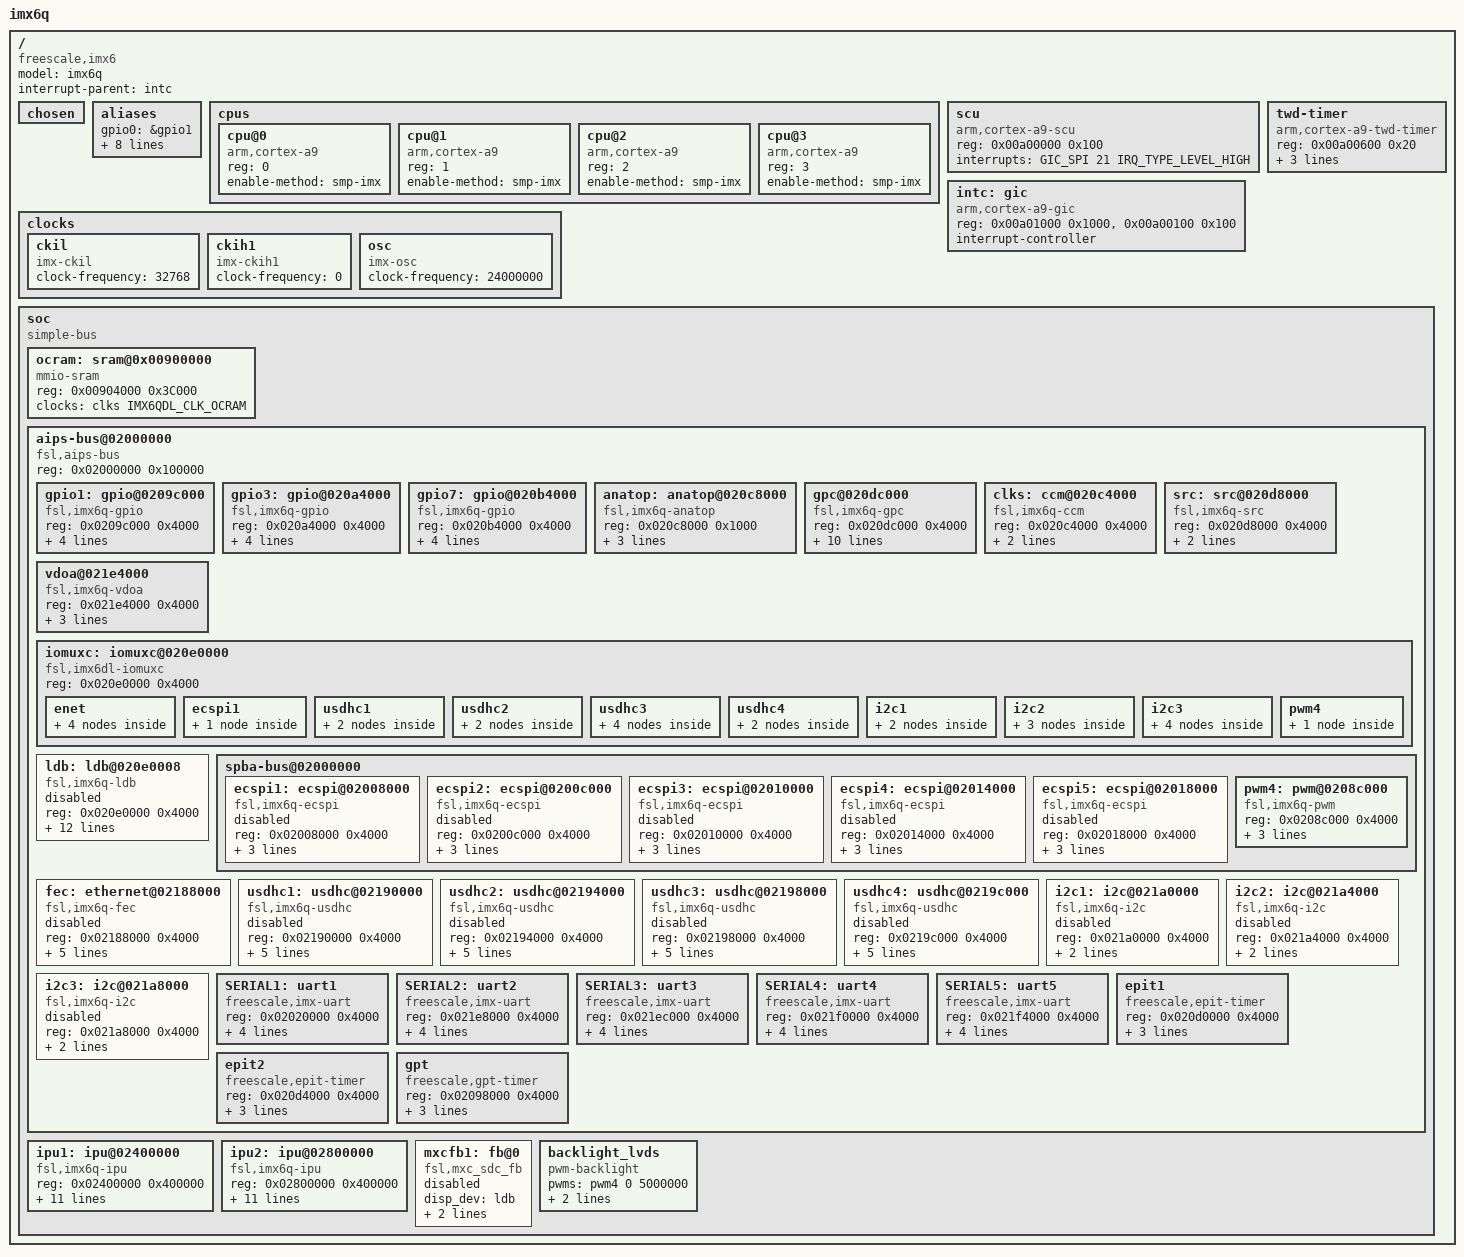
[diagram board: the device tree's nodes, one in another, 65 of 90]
/*
 * Copyright (C) 2014 Institut de Recherche Technologique SystemX and OpenWide.
 * Originally from Jean-Christophe Dubois, and modified by
 * Jimmy Durand Wesolowski (jimmy.durand-wesolowski@openwide.fr)
 * to split device tree files between i.MX6-specific and Sabrelite-specific
 * definitions, and add the Anatop definition.
 * Inspired by the Linux Kernel 3.13.6 i.MX6 device tree file.
 */

#include "imx6q-pinfunc.h"
#include <imx6qdl-clock.h>
#include <dt-bindings/interrupt-controller/arm-gic.h>

/memreserve/ 0x10000000 0x00001000;

/ {
	compatible = "freescale,imx6";
	model = "imx6q";
	interrupt-parent = <&intc>;
	#address-cells = <1>;
	#size-cells = <1>;

	chosen { };

	aliases {
                gpio0 = &gpio1;
                gpio2 = &gpio3;
                gpio6 = &gpio7;
		ipu0 = &ipu1;
		ipu1 = &ipu2;
		i2c0 = &i2c1;
		i2c1 = &i2c2;
		i2c2 = &i2c3;
                spi0 = &ecspi1;
	};

	cpus {
		#address-cells = <1>;
		#size-cells = <0>;

		cpu@0 {
			device_type = "cpu";
			compatible = "arm,cortex-a9";
			reg = <0>;
			enable-method = "smp-imx";
		};

		cpu@1 {
			device_type = "cpu";
			compatible = "arm,cortex-a9";
			reg = <1>;
			enable-method = "smp-imx";
		};

		cpu@2 {
			device_type = "cpu";
			compatible = "arm,cortex-a9";
			reg = <2>;
			enable-method = "smp-imx";
		};

		cpu@3 {
			device_type = "cpu";
			compatible = "arm,cortex-a9";
			reg = <3>;
			enable-method = "smp-imx";
		};
	};

        clocks {
		#address-cells = <1>;
		#size-cells = <0>;

		ckil {
			compatible = "imx-ckil", "fixed-clock";
			clock-frequency = <32768>;
		};

		ckih1 {
			compatible = "imx-ckih1", "fixed-clock";
			clock-frequency = <0>;
		};

		osc {
			compatible = "imx-osc", "fixed-clock";
			clock-frequency = <24000000>;
		};
	};

	scu { /* Snoop Control Unit */
      		compatible = "arm,cortex-a9-scu";
      		reg = <0x00a00000 0x100>;
		interrupts = <GIC_SPI 21 IRQ_TYPE_LEVEL_HIGH>;
	};

	intc: gic { /* Generic Interrupt Controller */
      		compatible = "arm,cortex-a9-gic";
		reg = <0x00a01000 0x1000>,
		      <0x00a00100 0x100>;
		#interrupt-cells = <3>;
		interrupt-controller;
	};

	twd-timer { /* Local Timer */
      		compatible = "arm,cortex-a9-twd-timer";
      		reg = <0x00a00600 0x20>;	/* Local timer registers */
		ref-counter-freq = <24000000>;	/* Reference counter frequency */
		interrupts = <GIC_PPI 13 (GIC_CPU_MASK_RAW(0xf) | IRQ_TYPE_EDGE_RISING)>;
	};

	soc {
		#address-cells = <1>;
		#size-cells = <1>;
		compatible = "simple-bus";

		ocram: sram@0x00900000 {
			compatible = "mmio-sram";
			reg = <0x00904000 0x3C000>;
			clocks = <&clks IMX6QDL_CLK_OCRAM>;
		};

		aips-bus@02000000 { /* AIPS1 */
			compatible = "fsl,aips-bus", "simple-bus";
			#address-cells = <1>;
			#size-cells = <1>;
			reg = <0x02000000 0x100000>;
			ranges;

			gpio1: gpio@0209c000 {
				compatible = "fsl,imx6q-gpio", "fsl,imx35-gpio";
				reg = <0x0209c000 0x4000>;
				interrupts = <GIC_SPI 66 IRQ_TYPE_LEVEL_HIGH>,
					     <GIC_SPI 67 IRQ_TYPE_LEVEL_HIGH>;
				gpio-controller;
				#gpio-cells = <2>;
				interrupt-controller;
				#interrupt-cells = <2>;
			};

			gpio3: gpio@020a4000 {
				compatible = "fsl,imx6q-gpio", "fsl,imx35-gpio";
				reg = <0x020a4000 0x4000>;
				interrupts = <GIC_SPI 70 IRQ_TYPE_LEVEL_HIGH>,
					     <GIC_SPI 71 IRQ_TYPE_LEVEL_HIGH>;
				gpio-controller;
				#gpio-cells = <2>;
				interrupt-controller;
				#interrupt-cells = <2>;
			};

			gpio7: gpio@020b4000 {
				compatible = "fsl,imx6q-gpio", "fsl,imx35-gpio";
				reg = <0x020b4000 0x4000>;
				interrupts = <GIC_SPI 78 IRQ_TYPE_LEVEL_HIGH>,
					     <GIC_SPI 79 IRQ_TYPE_LEVEL_HIGH>;
				gpio-controller;
				#gpio-cells = <2>;
				interrupt-controller;
				#interrupt-cells = <2>;
			};

			anatop: anatop@020c8000 {
				compatible = "fsl,imx6q-anatop", "syscon", "simple-bus";
				reg = <0x020c8000 0x1000>;
				interrupts = <GIC_SPI 49 IRQ_TYPE_LEVEL_HIGH>,
					     <GIC_SPI 54 IRQ_TYPE_LEVEL_HIGH>,
					     <GIC_SPI 127 IRQ_TYPE_LEVEL_HIGH>;
			};

			gpc@020dc000 {
				compatible = "fsl,imx6q-gpc";
				reg = <0x020dc000 0x4000>;
				interrupt-controller;
				#interrupt-cells = <3>;
				interrupts = <GIC_SPI 89 IRQ_TYPE_LEVEL_HIGH>,
					     <GIC_SPI 90 IRQ_TYPE_LEVEL_HIGH>;
				interrupt-parent = <&intc>;
				//pu-supply = <&reg_pu>;
				clocks = <&clks IMX6QDL_CLK_GPU3D_CORE>,
					 <&clks IMX6QDL_CLK_GPU3D_SHADER>,
					 <&clks IMX6QDL_CLK_GPU2D_CORE>,
					 <&clks IMX6QDL_CLK_GPU2D_AXI>,
					 <&clks IMX6QDL_CLK_OPENVG_AXI>,
					 <&clks IMX6QDL_CLK_VPU_AXI>;
				#power-domain-cells = <1>;
			};

			clks: ccm@020c4000 {
				compatible = "fsl,imx6q-ccm";
				reg = <0x020c4000 0x4000>;
				interrupts = <GIC_SPI 87 IRQ_TYPE_LEVEL_HIGH>,
					     <GIC_SPI 88 IRQ_TYPE_LEVEL_HIGH>;
				#clock-cells = <1>;
			};

			src: src@020d8000 {
				compatible = "fsl,imx6q-src", "fsl,imx51-src";
				reg = <0x020d8000 0x4000>;
				interrupts = <GIC_SPI 91 IRQ_TYPE_LEVEL_HIGH>,
					     <GIC_SPI 96 IRQ_TYPE_LEVEL_HIGH>;
				#reset-cells = <1>;
			};

			vdoa@021e4000 {
				compatible = "fsl,imx6q-vdoa";
				reg = <0x021e4000 0x4000>;
				interrupts = <GIC_SPI 8 IRQ_TYPE_LEVEL_HIGH>;
				clocks = <&clks IMX6QDL_CLK_VDOA>;
				iram = <&ocram>;
			};

			iomuxc: iomuxc@020e0000 {
				compatible = "fsl,imx6dl-iomuxc", "fsl,imx6q-iomuxc";
				reg = <0x020e0000 0x4000>;

				enet {
					pinctrl_enet_1: enetgrp-1 {
						fsl,pins = <
							MX6QDL_PAD_ENET_MDIO__ENET_MDIO       0x1b0b0
							MX6QDL_PAD_ENET_MDC__ENET_MDC         0x1b0b0
							MX6QDL_PAD_RGMII_TXC__RGMII_TXC       0x1b0b0
							MX6QDL_PAD_RGMII_TD0__RGMII_TD0       0x1b0b0
							MX6QDL_PAD_RGMII_TD1__RGMII_TD1       0x1b0b0
							MX6QDL_PAD_RGMII_TD2__RGMII_TD2       0x1b0b0
							MX6QDL_PAD_RGMII_TD3__RGMII_TD3       0x1b0b0
							MX6QDL_PAD_RGMII_TX_CTL__RGMII_TX_CTL 0x1b0b0
							MX6QDL_PAD_ENET_REF_CLK__ENET_TX_CLK  0x1b0b0
							MX6QDL_PAD_RGMII_RXC__RGMII_RXC       0x1b0b0
							MX6QDL_PAD_RGMII_RD0__RGMII_RD0       0x1b0b0
							MX6QDL_PAD_RGMII_RD1__RGMII_RD1       0x1b0b0
							MX6QDL_PAD_RGMII_RD2__RGMII_RD2       0x1b0b0
							MX6QDL_PAD_RGMII_RD3__RGMII_RD3       0x1b0b0
							MX6QDL_PAD_RGMII_RX_CTL__RGMII_RX_CTL 0x1b0b0
							MX6QDL_PAD_GPIO_16__ENET_REF_CLK      0x4001b0a8
						>;
					};

					pinctrl_enet_2: enetgrp-2 {
						fsl,pins = <
							MX6QDL_PAD_KEY_COL1__ENET_MDIO        0x1b0b0
							MX6QDL_PAD_KEY_COL2__ENET_MDC         0x1b0b0
							MX6QDL_PAD_RGMII_TXC__RGMII_TXC       0x1b0b0
							MX6QDL_PAD_RGMII_TD0__RGMII_TD0       0x1b0b0
							MX6QDL_PAD_RGMII_TD1__RGMII_TD1       0x1b0b0
							MX6QDL_PAD_RGMII_TD2__RGMII_TD2       0x1b0b0
							MX6QDL_PAD_RGMII_TD3__RGMII_TD3       0x1b0b0
							MX6QDL_PAD_RGMII_TX_CTL__RGMII_TX_CTL 0x1b0b0
							MX6QDL_PAD_ENET_REF_CLK__ENET_TX_CLK  0x1b0b0
							MX6QDL_PAD_RGMII_RXC__RGMII_RXC       0x1b0b0
							MX6QDL_PAD_RGMII_RD0__RGMII_RD0       0x1b0b0
							MX6QDL_PAD_RGMII_RD1__RGMII_RD1       0x1b0b0
							MX6QDL_PAD_RGMII_RD2__RGMII_RD2       0x1b0b0
							MX6QDL_PAD_RGMII_RD3__RGMII_RD3       0x1b0b0
							MX6QDL_PAD_RGMII_RX_CTL__RGMII_RX_CTL 0x1b0b0
						>;
					};

					pinctrl_enet_3: enetgrp-3 {
						fsl,pins = <
							MX6QDL_PAD_ENET_MDIO__ENET_MDIO       0x1b0b0
							MX6QDL_PAD_ENET_MDC__ENET_MDC         0x1b0b0
							MX6QDL_PAD_RGMII_TXC__RGMII_TXC       0x1b0b0
							MX6QDL_PAD_RGMII_TD0__RGMII_TD0       0x1b0b0
							MX6QDL_PAD_RGMII_TD1__RGMII_TD1       0x1b0b0
							MX6QDL_PAD_RGMII_TD2__RGMII_TD2       0x1b0b0
							MX6QDL_PAD_RGMII_TD3__RGMII_TD3       0x1b0b0
							MX6QDL_PAD_RGMII_TX_CTL__RGMII_TX_CTL 0x1b0b0
							MX6QDL_PAD_ENET_REF_CLK__ENET_TX_CLK  0x1b0b0
							MX6QDL_PAD_RGMII_RXC__RGMII_RXC       0x1b0b0
							MX6QDL_PAD_RGMII_RD0__RGMII_RD0       0x1b0b0
							MX6QDL_PAD_RGMII_RD1__RGMII_RD1       0x1b0b0
							MX6QDL_PAD_RGMII_RD2__RGMII_RD2       0x1b0b0
							MX6QDL_PAD_RGMII_RD3__RGMII_RD3       0x1b0b0
							MX6QDL_PAD_RGMII_RX_CTL__RGMII_RX_CTL 0x1b0b0
							MX6QDL_PAD_ENET_TX_EN__ENET_TX_EN     0x1b0b0
						>;
					};

					pinctrl_enet_4: enetgrp-4 {
						fsl,pins = <
							MX6QDL_PAD_ENET_MDIO__ENET_MDIO       0x100b0
							MX6QDL_PAD_ENET_MDC__ENET_MDC         0x100b0
							MX6QDL_PAD_RGMII_TXC__RGMII_TXC       0x100b0
							MX6QDL_PAD_RGMII_TD0__RGMII_TD0       0x100b0
							MX6QDL_PAD_RGMII_TD1__RGMII_TD1       0x100b0
							MX6QDL_PAD_RGMII_TD2__RGMII_TD2       0x100b0
							MX6QDL_PAD_RGMII_TD3__RGMII_TD3       0x100b0
							MX6QDL_PAD_RGMII_TX_CTL__RGMII_TX_CTL 0x100b0
							MX6QDL_PAD_ENET_REF_CLK__ENET_TX_CLK  0x100b0
							MX6QDL_PAD_RGMII_RXC__RGMII_RXC       0x1b0b0
							MX6QDL_PAD_RGMII_RD0__RGMII_RD0       0x1b0b0
							MX6QDL_PAD_RGMII_RD1__RGMII_RD1       0x1b0b0
							MX6QDL_PAD_RGMII_RD2__RGMII_RD2       0x1b0b0
							MX6QDL_PAD_RGMII_RD3__RGMII_RD3       0x1b0b0
							MX6QDL_PAD_RGMII_RX_CTL__RGMII_RX_CTL 0x1b0b0
						>;
					};
				};

				ecspi1 {
					pinctrl_ecspi1_1: ecspi1grp-1 {
						fsl,pins = <
							MX6QDL_PAD_EIM_D17__ECSPI1_MISO 0x100b1
							MX6QDL_PAD_EIM_D18__ECSPI1_MOSI 0x100b1
							MX6QDL_PAD_EIM_D16__ECSPI1_SCLK 0x100b1
						>;
					};
				};

				usdhc1 {
					pinctrl_usdhc1_1: usdhc1grp-1 {
						fsl,pins = <
							MX6QDL_PAD_SD1_CMD__SD1_CMD    0x17059
							MX6QDL_PAD_SD1_CLK__SD1_CLK    0x10059
							MX6QDL_PAD_SD1_DAT0__SD1_DATA0 0x17059
							MX6QDL_PAD_SD1_DAT1__SD1_DATA1 0x17059
							MX6QDL_PAD_SD1_DAT2__SD1_DATA2 0x17059
							MX6QDL_PAD_SD1_DAT3__SD1_DATA3 0x17059
							MX6QDL_PAD_NANDF_D0__SD1_DATA4 0x17059
							MX6QDL_PAD_NANDF_D1__SD1_DATA5 0x17059
							MX6QDL_PAD_NANDF_D2__SD1_DATA6 0x17059
							MX6QDL_PAD_NANDF_D3__SD1_DATA7 0x17059
						>;
					};

					pinctrl_usdhc1_2: usdhc1grp-2 {
						fsl,pins = <
							MX6QDL_PAD_SD1_CMD__SD1_CMD    0x17059
							MX6QDL_PAD_SD1_CLK__SD1_CLK    0x10059
							MX6QDL_PAD_SD1_DAT0__SD1_DATA0 0x17059
							MX6QDL_PAD_SD1_DAT1__SD1_DATA1 0x17059
							MX6QDL_PAD_SD1_DAT2__SD1_DATA2 0x17059
							MX6QDL_PAD_SD1_DAT3__SD1_DATA3 0x17059
						>;
					};
				};

				usdhc2 {
					pinctrl_usdhc2_1: usdhc2grp-1 {
						fsl,pins = <
							MX6QDL_PAD_SD2_CMD__SD2_CMD    0x17059
							MX6QDL_PAD_SD2_CLK__SD2_CLK    0x10059
							MX6QDL_PAD_SD2_DAT0__SD2_DATA0 0x17059
							MX6QDL_PAD_SD2_DAT1__SD2_DATA1 0x17059
							MX6QDL_PAD_SD2_DAT2__SD2_DATA2 0x17059
							MX6QDL_PAD_SD2_DAT3__SD2_DATA3 0x17059
							MX6QDL_PAD_NANDF_D4__SD2_DATA4 0x17059
							MX6QDL_PAD_NANDF_D5__SD2_DATA5 0x17059
							MX6QDL_PAD_NANDF_D6__SD2_DATA6 0x17059
							MX6QDL_PAD_NANDF_D7__SD2_DATA7 0x17059
						>;
					};

					pinctrl_usdhc2_2: usdhc2grp-2 {
						fsl,pins = <
							MX6QDL_PAD_SD2_CMD__SD2_CMD    0x17059
							MX6QDL_PAD_SD2_CLK__SD2_CLK    0x10059
							MX6QDL_PAD_SD2_DAT0__SD2_DATA0 0x17059
							MX6QDL_PAD_SD2_DAT1__SD2_DATA1 0x17059
							MX6QDL_PAD_SD2_DAT2__SD2_DATA2 0x17059
							MX6QDL_PAD_SD2_DAT3__SD2_DATA3 0x17059
						>;
					};
				};

				usdhc3 {
					pinctrl_usdhc3_1: usdhc3grp-1 {
						fsl,pins = <
							MX6QDL_PAD_SD3_CMD__SD3_CMD    0x17059
							MX6QDL_PAD_SD3_CLK__SD3_CLK    0x10059
							MX6QDL_PAD_SD3_DAT0__SD3_DATA0 0x17059
							MX6QDL_PAD_SD3_DAT1__SD3_DATA1 0x17059
							MX6QDL_PAD_SD3_DAT2__SD3_DATA2 0x17059
							MX6QDL_PAD_SD3_DAT3__SD3_DATA3 0x17059
							MX6QDL_PAD_SD3_DAT4__SD3_DATA4 0x17059
							MX6QDL_PAD_SD3_DAT5__SD3_DATA5 0x17059
							MX6QDL_PAD_SD3_DAT6__SD3_DATA6 0x17059
							MX6QDL_PAD_SD3_DAT7__SD3_DATA7 0x17059
						>;
					};

					pinctrl_usdhc3_1_100mhz: usdhc3grp-1-100mhz { /* 100Mhz */
						fsl,pins = <
							MX6QDL_PAD_SD3_CMD__SD3_CMD 0x170b9
							MX6QDL_PAD_SD3_CLK__SD3_CLK 0x100b9
							MX6QDL_PAD_SD3_DAT0__SD3_DATA0 0x170b9
							MX6QDL_PAD_SD3_DAT1__SD3_DATA1 0x170b9
							MX6QDL_PAD_SD3_DAT2__SD3_DATA2 0x170b9
							MX6QDL_PAD_SD3_DAT3__SD3_DATA3 0x170b9
							MX6QDL_PAD_SD3_DAT4__SD3_DATA4 0x170b9
							MX6QDL_PAD_SD3_DAT5__SD3_DATA5 0x170b9
							MX6QDL_PAD_SD3_DAT6__SD3_DATA6 0x170b9
							MX6QDL_PAD_SD3_DAT7__SD3_DATA7 0x170b9
						>;
					};

					pinctrl_usdhc3_1_200mhz: usdhc3grp-1-200mhz { /* 200Mhz */
						fsl,pins = <
							MX6QDL_PAD_SD3_CMD__SD3_CMD 0x170f9
							MX6QDL_PAD_SD3_CLK__SD3_CLK 0x100f9
							MX6QDL_PAD_SD3_DAT0__SD3_DATA0 0x170f9
							MX6QDL_PAD_SD3_DAT1__SD3_DATA1 0x170f9
							MX6QDL_PAD_SD3_DAT2__SD3_DATA2 0x170f9
							MX6QDL_PAD_SD3_DAT3__SD3_DATA3 0x170f9
							MX6QDL_PAD_SD3_DAT4__SD3_DATA4 0x170f9
							MX6QDL_PAD_SD3_DAT5__SD3_DATA5 0x170f9
							MX6QDL_PAD_SD3_DAT6__SD3_DATA6 0x170f9
							MX6QDL_PAD_SD3_DAT7__SD3_DATA7 0x170f9
						>;
					};

					pinctrl_usdhc3_2: usdhc3grp-2 {
						fsl,pins = <
							MX6QDL_PAD_SD3_CMD__SD3_CMD    0x17059
							MX6QDL_PAD_SD3_CLK__SD3_CLK    0x10059
							MX6QDL_PAD_SD3_DAT0__SD3_DATA0 0x17059
							MX6QDL_PAD_SD3_DAT1__SD3_DATA1 0x17059
							MX6QDL_PAD_SD3_DAT2__SD3_DATA2 0x17059
							MX6QDL_PAD_SD3_DAT3__SD3_DATA3 0x17059
						>;
					};
				};

				usdhc4 {
					pinctrl_usdhc4_1: usdhc4grp-1 {
						fsl,pins = <
							MX6QDL_PAD_SD4_CMD__SD4_CMD    0x17059
							MX6QDL_PAD_SD4_CLK__SD4_CLK    0x10059
							MX6QDL_PAD_SD4_DAT0__SD4_DATA0 0x17059
							MX6QDL_PAD_SD4_DAT1__SD4_DATA1 0x17059
							MX6QDL_PAD_SD4_DAT2__SD4_DATA2 0x17059
							MX6QDL_PAD_SD4_DAT3__SD4_DATA3 0x17059
							MX6QDL_PAD_SD4_DAT4__SD4_DATA4 0x17059
							MX6QDL_PAD_SD4_DAT5__SD4_DATA5 0x17059
							MX6QDL_PAD_SD4_DAT6__SD4_DATA6 0x17059
							MX6QDL_PAD_SD4_DAT7__SD4_DATA7 0x17059
						>;
					};

					pinctrl_usdhc4_2: usdhc4grp-2 {
						fsl,pins = <
							MX6QDL_PAD_SD4_CMD__SD4_CMD    0x17059
							MX6QDL_PAD_SD4_CLK__SD4_CLK    0x10059
							MX6QDL_PAD_SD4_DAT0__SD4_DATA0 0x17059
							MX6QDL_PAD_SD4_DAT1__SD4_DATA1 0x17059
							MX6QDL_PAD_SD4_DAT2__SD4_DATA2 0x17059
							MX6QDL_PAD_SD4_DAT3__SD4_DATA3 0x17059
						>;
					};
				};

				i2c1 {
					pinctrl_i2c1_1: i2c1grp-1 {
						fsl,pins = <
							MX6QDL_PAD_EIM_D21__I2C1_SCL 0x4001b8b1
							MX6QDL_PAD_EIM_D28__I2C1_SDA 0x4001b8b1
						>;
					};

					pinctrl_i2c1_2: i2c1grp-2 {
						fsl,pins = <
							MX6QDL_PAD_CSI0_DAT8__I2C1_SDA 0x4001b8b1
							MX6QDL_PAD_CSI0_DAT9__I2C1_SCL 0x4001b8b1
						>;
					};
				};

				i2c2 {
					pinctrl_i2c2_1: i2c2grp-1 {
						fsl,pins = <
							MX6QDL_PAD_EIM_EB2__I2C2_SCL 0x4001b8b1
							MX6QDL_PAD_EIM_D16__I2C2_SDA 0x4001b8b1
						>;
					};

					pinctrl_i2c2_2: i2c2grp-2 {
						fsl,pins = <
							MX6QDL_PAD_KEY_COL3__I2C2_SCL 0x4001b8b1
							MX6QDL_PAD_KEY_ROW3__I2C2_SDA 0x4001b8b1
						>;
					};

					pinctrl_i2c2_3: i2c2grp-3 {
						fsl,pins = <
							MX6QDL_PAD_EIM_EB2__I2C2_SCL  0x4001b8b1
							MX6QDL_PAD_KEY_ROW3__I2C2_SDA 0x4001b8b1
						>;
					};
				};

				i2c3 {
					pinctrl_i2c3_1: i2c3grp-1 {
						fsl,pins = <
							MX6QDL_PAD_EIM_D17__I2C3_SCL 0x4001b8b1
							MX6QDL_PAD_EIM_D18__I2C3_SDA 0x4001b8b1
						>;
					};

					pinctrl_i2c3_2: i2c3grp-2 {
						fsl,pins = <
							MX6QDL_PAD_GPIO_3__I2C3_SCL 0x4001b8b1
							MX6QDL_PAD_GPIO_6__I2C3_SDA 0x4001b8b1
						>;
					};

					pinctrl_i2c3_3: i2c3grp-3 {
						fsl,pins = <
							MX6QDL_PAD_GPIO_5__I2C3_SCL  0x4001b8b1
							MX6QDL_PAD_GPIO_16__I2C3_SDA 0x4001b8b1
						>;
					};

					pinctrl_i2c3_4: i2c3grp-4 {
						fsl,pins = <
							MX6QDL_PAD_GPIO_3__I2C3_SCL  0x4001b8b1
							MX6QDL_PAD_EIM_D18__I2C3_SDA 0x4001b8b1
						>;
					};
				};

				pwm4 {
					pinctrl_pwm4: pwm4grp {
						fsl,pins = <
							MX6QDL_PAD_SD1_CMD__PWM4_OUT 0x1b0b1
						>;
					};
				};
			};

			ldb: ldb@020e0008 {
				compatible = "fsl,imx6q-ldb", "fsl,imx53-ldb";
				reg = <0x020e0000 0x4000>;
				clocks = <&clks IMX6QDL_CLK_LDB_DI0>,
					 <&clks IMX6QDL_CLK_LDB_DI1>,
					 <&clks IMX6QDL_CLK_IPU1_DI0_SEL>,
					 <&clks IMX6QDL_CLK_IPU1_DI1_SEL>,
					 <&clks IMX6QDL_CLK_IPU2_DI0_SEL>,
					 <&clks IMX6QDL_CLK_IPU2_DI1_SEL>,
					 <&clks IMX6QDL_CLK_LDB_DI0_DIV_3_5>,
					 <&clks IMX6QDL_CLK_LDB_DI1_DIV_3_5>,
					 <&clks IMX6QDL_CLK_LVDS1_SEL>,
					 <&clks IMX6QDL_CLK_LVDS2_SEL>,
					 <&clks IMX6QDL_CLK_LVDS1_GATE>,
					 <&clks IMX6QDL_CLK_LVDS2_GATE>;
				clock-names = "ldb_di0", "ldb_di1",
				"ipu1_di0_sel", "ipu1_di1_sel",
				"ipu2_di0_sel", "ipu2_di1_sel",
				"di0_div_3_5", "di1_div_3_5",
				"di0_div_7", "di1_div_7",
				"di0_div_sel", "di1_div_sel";
				status = "disabled";
			};

			spba-bus@02000000 {
				#address-cells = <1>;
				#size-cells = <1>;

				ecspi1: ecspi@02008000 {
					compatible = "fsl,imx6q-ecspi", "fsl,imx51-ecspi";
					reg = <0x02008000 0x4000>;
					interrupts = <GIC_SPI 31 IRQ_TYPE_LEVEL_HIGH>;
					clocks = <&clks IMX6QDL_CLK_ECSPI1>,
						 <&clks IMX6QDL_CLK_ECSPI1>;
					clock-names = "ipg", "per";
					status = "disabled";
				};

				ecspi2: ecspi@0200c000 {
					compatible = "fsl,imx6q-ecspi", "fsl,imx51-ecspi";
					reg = <0x0200c000 0x4000>;
					interrupts = <GIC_SPI 32 IRQ_TYPE_LEVEL_HIGH>;
					clocks = <&clks IMX6QDL_CLK_ECSPI2>,
						 <&clks IMX6QDL_CLK_ECSPI2>;
					clock-names = "ipg", "per";
					status = "disabled";
				};

				ecspi3: ecspi@02010000 {
					compatible = "fsl,imx6q-ecspi", "fsl,imx51-ecspi";
					reg = <0x02010000 0x4000>;
					interrupts = <GIC_SPI 33 IRQ_TYPE_LEVEL_HIGH>;
					clocks = <&clks IMX6QDL_CLK_ECSPI3>,
						 <&clks IMX6QDL_CLK_ECSPI3>;
					clock-names = "ipg", "per";
					status = "disabled";
				};

				ecspi4: ecspi@02014000 {
					compatible = "fsl,imx6q-ecspi", "fsl,imx51-ecspi";
					reg = <0x02014000 0x4000>;
					interrupts = <GIC_SPI 34 IRQ_TYPE_LEVEL_HIGH>;
					clocks = <&clks IMX6QDL_CLK_ECSPI4>,
						 <&clks IMX6QDL_CLK_ECSPI4>;
					clock-names = "ipg", "per";
					status = "disabled";
				};

				ecspi5: ecspi@02018000 {
					compatible = "fsl,imx6q-ecspi", "fsl,imx51-ecspi";
					reg = <0x02018000 0x4000>;
					interrupts = <GIC_SPI 35 IRQ_TYPE_LEVEL_HIGH>;
					clocks = <&clks IMX6Q_CLK_ECSPI5>,
						 <&clks IMX6Q_CLK_ECSPI5>;
					clock-names = "ipg", "per";
					status = "disabled";
				};

				pwm4: pwm@0208c000 {
					#pwm-cells = <2>;
					compatible = "fsl,imx6q-pwm", "fsl,imx27-pwm";
					reg = <0x0208c000 0x4000>;
					interrupts = <GIC_SPI 86 IRQ_TYPE_LEVEL_HIGH>;
					clocks = <&clks IMX6QDL_CLK_IPG>,
						 <&clks IMX6QDL_CLK_PWM4>;
					clock-names = "ipg", "per";
				};
			};

			fec: ethernet@02188000 {
				compatible = "fsl,imx6q-fec";
				reg = <0x02188000 0x4000>;
				/* interrupts-extended = */
				/* 	<&intc 0 118 IRQ_TYPE_LEVEL_HIGH>, */
				/* 	<&intc 0 119 IRQ_TYPE_LEVEL_HIGH>; */
				interrupts = <GIC_SPI 118 IRQ_TYPE_LEVEL_HIGH>,
					     <GIC_SPI 119 IRQ_TYPE_LEVEL_HIGH>;
				clocks = <&clks IMX6QDL_CLK_ENET>,
					 <&clks IMX6QDL_CLK_ENET>,
					 <&clks IMX6QDL_CLK_ENET_REF>;
				clock-names = "ipg", "ahb", "ptp";
				status = "disabled";
			};

			usdhc1: usdhc@02190000 {
				compatible = "fsl,imx6q-usdhc";
				reg = <0x02190000 0x4000>;
				interrupts = <GIC_SPI 22 IRQ_TYPE_LEVEL_HIGH>;
				clocks = <&clks IMX6QDL_CLK_USDHC1>,
					 <&clks IMX6QDL_CLK_USDHC1>,
					 <&clks IMX6QDL_CLK_USDHC1>;
				clock-names = "ipg", "ahb", "per";
				bus-width = <4>;
				status = "disabled";
			};

			usdhc2: usdhc@02194000 {
				compatible = "fsl,imx6q-usdhc";
				reg = <0x02194000 0x4000>;
				interrupts = <GIC_SPI 23 IRQ_TYPE_LEVEL_HIGH>;
				clocks = <&clks IMX6QDL_CLK_USDHC2>,
					 <&clks IMX6QDL_CLK_USDHC2>,
					 <&clks IMX6QDL_CLK_USDHC2>;
				clock-names = "ipg", "ahb", "per";
				bus-width = <4>;
				status = "disabled";
			};

			usdhc3: usdhc@02198000 {
				compatible = "fsl,imx6q-usdhc";
				reg = <0x02198000 0x4000>;
				interrupts = <GIC_SPI 24 IRQ_TYPE_LEVEL_HIGH>;
				clocks = <&clks IMX6QDL_CLK_USDHC3>,
					 <&clks IMX6QDL_CLK_USDHC3>,
					 <&clks IMX6QDL_CLK_USDHC3>;
				clock-names = "ipg", "ahb", "per";
				bus-width = <4>;
				status = "disabled";
			};

			usdhc4: usdhc@0219c000 {
				compatible = "fsl,imx6q-usdhc";
				reg = <0x0219c000 0x4000>;
				interrupts = <GIC_SPI 25 IRQ_TYPE_LEVEL_HIGH>;
				clocks = <&clks IMX6QDL_CLK_USDHC4>,
					 <&clks IMX6QDL_CLK_USDHC4>,
					 <&clks IMX6QDL_CLK_USDHC4>;
				clock-names = "ipg", "ahb", "per";
				bus-width = <4>;
				status = "disabled";
			};

			i2c1: i2c@021a0000 {
				#address-cells = <1>;
				#size-cells = <0>;
				compatible = "fsl,imx6q-i2c", "fsl,imx21-i2c";
				reg = <0x021a0000 0x4000>;
				interrupts = <GIC_SPI 36 IRQ_TYPE_LEVEL_HIGH>;
				clocks = <&clks IMX6QDL_CLK_I2C1>;
				status = "disabled";
			};

			i2c2: i2c@021a4000 {
				#address-cells = <1>;
				#size-cells = <0>;
				compatible = "fsl,imx6q-i2c", "fsl,imx21-i2c";
				reg = <0x021a4000 0x4000>;
				interrupts = <GIC_SPI 37 IRQ_TYPE_LEVEL_HIGH>;
				clocks = <&clks IMX6QDL_CLK_I2C2>;
				status = "disabled";
			};

			i2c3: i2c@021a8000 {
				#address-cells = <1>;
				#size-cells = <0>;
				compatible = "fsl,imx6q-i2c", "fsl,imx21-i2c";
				reg = <0x021a8000 0x4000>;
				interrupts = <GIC_SPI 38 IRQ_TYPE_LEVEL_HIGH>;
				clocks = <&clks IMX6QDL_CLK_I2C3>;
				status = "disabled";
			};

			SERIAL1: uart1 {
				compatible = "freescale,imx-uart";
				reg = <0x02020000 0x4000>;
                                clocks = <&clks IMX6QDL_CLK_UART_IPG>,
					 <&clks IMX6QDL_CLK_UART_SERIAL>;
                                clock-names = "ipg", "per";
				clock-frequency = <80000000>;
				interrupts = <GIC_SPI 26 IRQ_TYPE_LEVEL_HIGH>;
			};

			SERIAL2: uart2 {
				compatible = "freescale,imx-uart";
				reg = <0x021e8000 0x4000>;
                                clocks = <&clks IMX6QDL_CLK_UART_IPG>,
					 <&clks IMX6QDL_CLK_UART_SERIAL>;
                                clock-names = "ipg", "per";
				clock-frequency = <80000000>;
				interrupts = <GIC_SPI 27 IRQ_TYPE_LEVEL_HIGH>;
			};

			SERIAL3: uart3 {
				compatible = "freescale,imx-uart";
				reg = <0x021ec000 0x4000>;
                                clocks = <&clks IMX6QDL_CLK_UART_IPG>,
					 <&clks IMX6QDL_CLK_UART_SERIAL>;
                                clock-names = "ipg", "per";
				clock-frequency = <80000000>;
				interrupts = <GIC_SPI 28 IRQ_TYPE_LEVEL_HIGH>;
			};

			SERIAL4: uart4 {
				compatible = "freescale,imx-uart";
				reg = <0x021f0000 0x4000>;
                                clocks = <&clks IMX6QDL_CLK_UART_IPG>,
					 <&clks IMX6QDL_CLK_UART_SERIAL>;
                                clock-names = "ipg", "per";
				clock-frequency = <80000000>;
				interrupts = <GIC_SPI 29 IRQ_TYPE_LEVEL_HIGH>;
			};

			SERIAL5: uart5 {
				compatible = "freescale,imx-uart";
				reg = <0x021f4000 0x4000>;
                                clocks = <&clks IMX6QDL_CLK_UART_IPG>,
					 <&clks IMX6QDL_CLK_UART_SERIAL>;
                                clock-names = "ipg", "per";
				clock-frequency = <80000000>;
				interrupts = <GIC_SPI 30 IRQ_TYPE_LEVEL_HIGH>;
			};

			epit1 {
				compatible = "freescale,epit-timer";
				reg = <0x020d0000 0x4000>;
				clock-frequency = <38999040>;
				timer_num = <0>;
				interrupts = <GIC_SPI 56 IRQ_TYPE_LEVEL_HIGH>;
			};

			epit2 {
				compatible = "freescale,epit-timer";
				reg = <0x020d4000 0x4000>;
				clock-frequency = <38999040>;
				timer_num = <1>;
				interrupts = <GIC_SPI 57 IRQ_TYPE_LEVEL_HIGH>;
			};

			gpt {
				compatible = "freescale,gpt-timer";
				reg = <0x02098000 0x4000>;
				clock-frequency = <32000>;
				timer_num = <2>;
				interrupts = <GIC_SPI 55 IRQ_TYPE_LEVEL_HIGH>;
			};
		};

		ipu1: ipu@02400000 {
			compatible = "fsl,imx6q-ipu";
			reg = <0x02400000 0x400000>;
			interrupts = <GIC_SPI 6 IRQ_TYPE_LEVEL_HIGH>,
				     <GIC_SPI 5 IRQ_TYPE_LEVEL_HIGH>;
			clocks = <&clks IMX6QDL_CLK_IPU1>,
				 <&clks IMX6QDL_CLK_IPU1_DI0>,
				 <&clks IMX6QDL_CLK_IPU1_DI1>,
				 <&clks IMX6QDL_CLK_IPU1_DI0_SEL>,
				 <&clks IMX6QDL_CLK_IPU1_DI1_SEL>,
				 <&clks IMX6QDL_CLK_LDB_DI0>,
				 <&clks IMX6QDL_CLK_LDB_DI1>;
			clock-names = "bus", "di0", "di1",
				      "di0_sel", "di1_sel",
				      "ldb_di0", "ldb_di1";
			resets = <&src 2>;
			bypass_reset = <0>;
		};

		ipu2: ipu@02800000 {
			compatible = "fsl,imx6q-ipu";
			reg = <0x02800000 0x400000>;
			interrupts = <GIC_SPI 8 IRQ_TYPE_LEVEL_HIGH>,
				     <GIC_SPI 7 IRQ_TYPE_LEVEL_HIGH>;
			clocks = <&clks IMX6QDL_CLK_IPU2>,
				 <&clks IMX6QDL_CLK_IPU2_DI0>,
				 <&clks IMX6QDL_CLK_IPU2_DI1>,
				 <&clks IMX6QDL_CLK_IPU2_DI0_SEL>,
				 <&clks IMX6QDL_CLK_IPU2_DI1_SEL>,
				 <&clks IMX6QDL_CLK_LDB_DI0>,
				 <&clks IMX6QDL_CLK_LDB_DI1>;
			clock-names = "bus", "di0", "di1",
				      "di0_sel", "di1_sel",
				      "ldb_di0", "ldb_di1";
			resets = <&src 4>;
			bypass_reset = <0>;
		};

		mxcfb1: fb@0 {
			compatible = "fsl,mxc_sdc_fb";
			disp_dev = "ldb";
			int_clk = <0>;
			late_init = <0>;
			status = "disabled";
		};

		backlight_lvds {
			compatible = "pwm-backlight";
			pwms = <&pwm4 0 5000000>;
			brightness-levels = <0 4 8 16 32 64 128 255>;
			default-brightness-level = <7>;
			/* power-supply = <&reg_3p3v>; */
			status = "okay";
		};
	};
};


